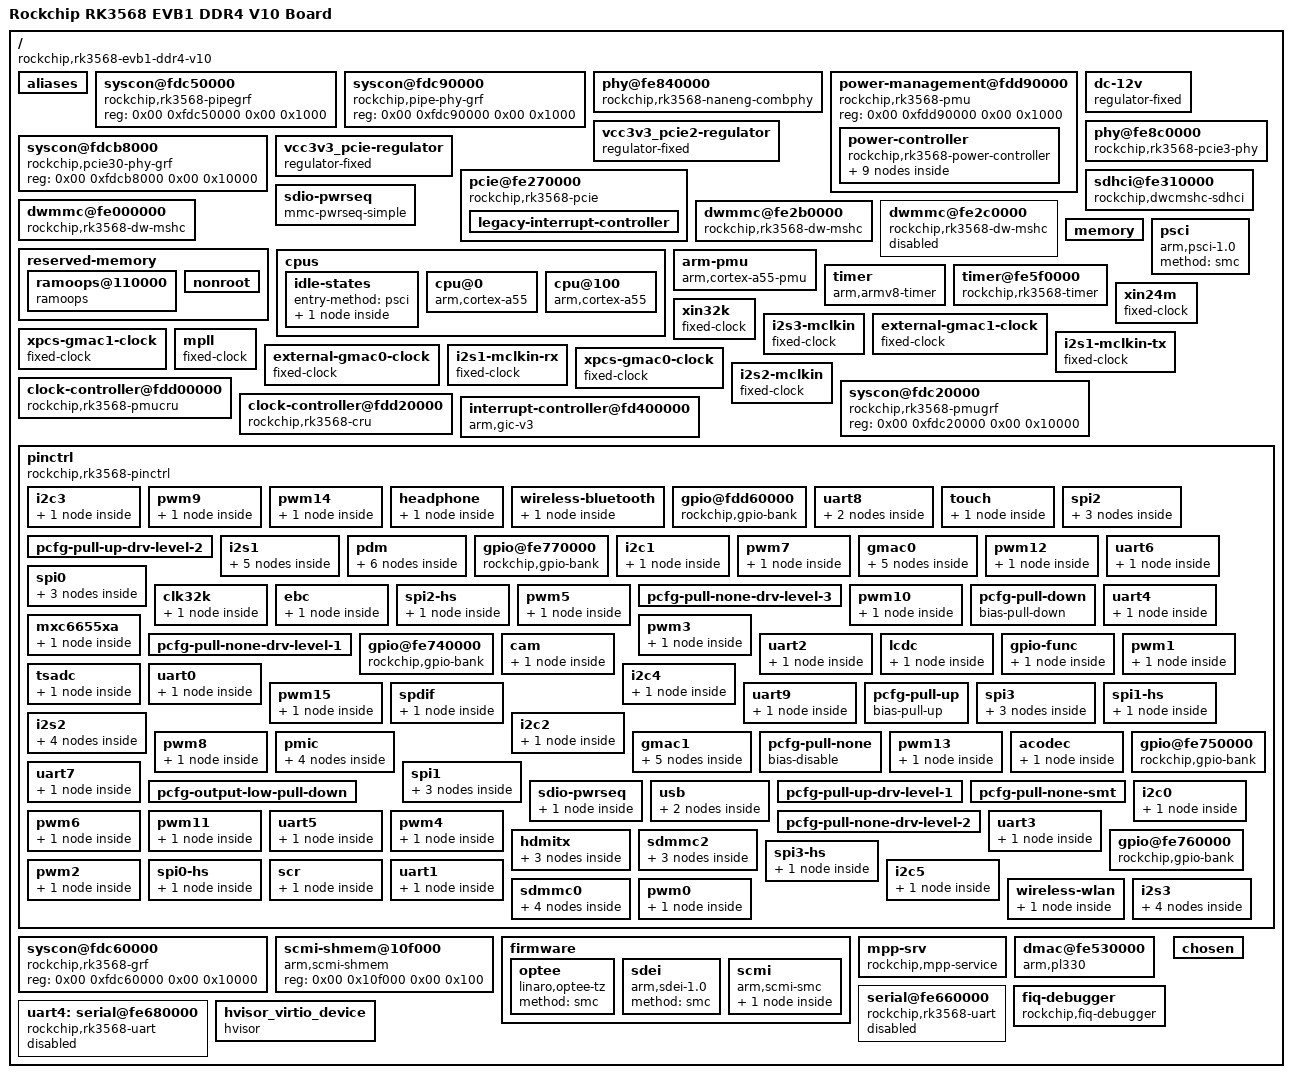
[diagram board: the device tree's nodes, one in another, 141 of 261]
/dts-v1/;

/{
    #address-cells = <0x02>;
	model = "Rockchip RK3568 EVB1 DDR4 V10 Board";
	serial-number = "7256eeaa4ea280de";
	#size-cells = <0x02>;
	interrupt-parent = <0x01>;
	compatible = "rockchip,rk3568-evb1-ddr4-v10\0rockchip,rk3568";

	aliases {
		mmc0 = "/sdhci@fe310000";
		serial2 = "/serial@fe660000";
		sdmmc2 = "/dwmmc@fe000000";
		serial4 = "/serial@fe680000";
		mmc1 = "/dwmmc@fe2b0000";
		mmc2 = "/dwmmc@fe2c0000";
		mmc3 = "/dwmmc@fe000000";
	};

	syscon@fdc50000 {
		compatible = "rockchip,rk3568-pipegrf\0syscon";
		reg = <0x00 0xfdc50000 0x00 0x1000>;
		phandle = <0x10d>;
	};

	syscon@fdc90000 {
		compatible = "rockchip,pipe-phy-grf\0syscon";
		reg = <0x00 0xfdc90000 0x00 0x1000>;
		phandle = <0x110>;
	};

	phy@fe840000 {
		rockchip,pipe-grf = <0x10d>;
		clock-names = "refclk\0apbclk\0pipe_clk";
		assigned-clocks = <0x33 0x25>;
		assigned-clock-rates = <0x5f5e100>;
		resets = <0x20 0x1c8 0x20 0x1c9>;
		clocks = <0x33 0x25 0x20 0x17e 0x20 0x7f>;
		#phy-cells = <0x01>;
		compatible = "rockchip,rk3568-naneng-combphy";
		status = "okay";
		rockchip,pipe-phy-grf = <0x110>;
		reg = <0x00 0xfe840000 0x00 0x100>;
		phandle = <0x24>;
		reset-names = "combphy-apb\0combphy";
	};

	power-management@fdd90000 {
		compatible = "rockchip,rk3568-pmu\0syscon\0simple-mfd";
		reg = <0x00 0xfdd90000 0x00 0x1000>;
		phandle = <0x177>;

		power-controller {
			#address-cells = <0x01>;
			#size-cells = <0x00>;
			#power-domain-cells = <0x01>;
			compatible = "rockchip,rk3568-power-controller";
			status = "okay";
			phandle = <0x22>;

			pd_pipe@15 {
				clocks = <0x20 0x7f>;
				reg = <0x0f>;
				pm_qos = <0x5a 0x5b 0x5c 0x5d 0x5e 0x5f 0x60 0x61>;
			};

			pd_vi@8 {
				clocks = <0x20 0xcc 0x20 0xcd>;
				reg = <0x08>;
				pm_qos = <0x49 0x4a 0x4b>;
			};

			pd_rkvenc@14 {
				clocks = <0x20 0x102>;
				reg = <0x0e>;
				pm_qos = <0x57 0x58 0x59>;
			};

			pd_rga@10 {
				clocks = <0x20 0xf1 0x20 0xf2>;
				reg = <0x0a>;
				pm_qos = <0x4f 0x50 0x51 0x52 0x53 0x54>;
			};

			pd_vpu@11 {
				clocks = <0x20 0xed>;
				reg = <0x0b>;
				pm_qos = <0x55>;
			};

			pd_gpu@7 {
				clocks = <0x20 0x19 0x20 0x1a>;
				reg = <0x07>;
				pm_qos = <0x48>;
			};

			pd_rkvdec@13 {
				clocks = <0x20 0x107>;
				reg = <0x0d>;
				pm_qos = <0x56>;
			};

			pd_vo@9 {
				clocks = <0x20 0xda 0x20 0xdb 0x20 0xdc>;
				reg = <0x09>;
				pm_qos = <0x4c 0x4d 0x4e>;
			};

			pd_npu@6 {
				clocks = <0x20 0x27 0x20 0x25 0x20 0x26>;
				reg = <0x06>;
				pm_qos = <0x47>;
			};
		};
	};

	dc-12v {
		regulator-max-microvolt = <0xb71b00>;
		regulator-boot-on;
		regulator-always-on;
		regulator-min-microvolt = <0xb71b00>;
		regulator-name = "dc_12v";
		compatible = "regulator-fixed";
		phandle = <0x131>;
	};

	vcc3v3_pcie2-regulator {
		regulator-max-microvolt = <0x325aa0>;
		regulator-boot-on;
		gpio = <0x38 0x17 0x00>;
		regulator-always-on;
		enable-active-high;
		regulator-min-microvolt = <0x325aa0>;
		regulator-name = "vcc3v3_pcie2";
		startup-delay-us = <0x1388>;
		compatible = "regulator-fixed";
		phandle = <0x1ea>;
		vin-supply = <0x131>;
	};


	// pcie@fe260000 {
	// 	power-domains = <0x22 0x0f>;
	// 	#address-cells = <0x03>;
	// 	phy-names = "pcie-phy";
	// 	bus-range = <0x00 0x0f>;
	// 	clock-names = "aclk_mst\0aclk_slv\0aclk_dbi\0pclk\0aux";
	// 	reg-names = "pcie-dbi\0pcie-apb";
	// 	num-ob-windows = <0x02>;
	// 	resets = <0x20 0xa1>;
	// 	interrupts = <0x00 0x4b 0x04 0x00 0x4a 0x04 0x00 0x49 0x04 0x00 0x48 0x04 0x00 0x47 0x04>;
	// 	clocks = <0x20 0x81 0x20 0x82 0x20 0x83 0x20 0x84 0x20 0x85>;
	// 	interrupt-map = <0x00 0x00 0x00 0x01 0xac 0x00 0x00 0x00 0x00 0x02 0xac 0x01 0x00 0x00 0x00 0x03 0xac 0x02 0x00 0x00 0x00 0x04 0xac 0x03>;
	// 	#size-cells = <0x02>;
	// 	max-link-speed = <0x02>;
	// 	device_type = "pci";
	// 	interrupt-map-mask = <0x00 0x00 0x00 0x07>;
	// 	reset-gpios = <0x83 0x11 0x00>;
	// 	num-lanes = <0x01>;
	// 	compatible = "rockchip,rk3568-pcie\0snps,dw-pcie";
	// 	ranges = <0x800 0x00 0xf4000000 0x00 0xf4000000 0x00 0x100000 0x81000000 0x00 0xf4100000 0x00 0xf4100000 0x00 0x100000 0x82000000 0x00 0xf4200000 0x00 0xf4200000 0x00 0x1e00000 0xc3000000 0x03 0x00 0x03 0x00 0x00 0x40000000>;
	// 	msi-map = <0x00 0xad 0x00 0x1000>;
	// 	#interrupt-cells = <0x01>;
	// 	status = "okay";
	// 	interrupt-names = "sys\0pmc\0msg\0legacy\0err";
	// 	phys = <0x24 0x02>;
	// 	num-viewport = <0x08>;
	// 	reg = <0x03 0xc0000000 0x00 0x400000 0x00 0xfe260000 0x00 0x10000>;
	// 	linux,pci-domain = <0x00>;
	// 	phandle = <0x19d>;
	// 	reset-names = "pipe";
	// 	num-ib-windows = <0x06>;

	// 	legacy-interrupt-controller {
	// 		#address-cells = <0x00>;
	// 		interrupts = <0x00 0x48 0x01>;
	// 		interrupt-parent = <0x01>;
	// 		#interrupt-cells = <0x01>;
	// 		phandle = <0xac>;
	// 		interrupt-controller;
	// 	};
	// };

	syscon@fdcb8000 {
		compatible = "rockchip,pcie30-phy-grf\0syscon";
		reg = <0x00 0xfdcb8000 0x00 0x10000>;
		phandle = <0x116>;
	};

	phy@fe8c0000 {
		clock-names = "refclk_m\0refclk_n\0pclk";
		resets = <0x20 0x1be>;
		clocks = <0x33 0x26 0x33 0x27 0x20 0x177>;
		#phy-cells = <0x00>;
		compatible = "rockchip,rk3568-pcie3-phy";
		status = "okay";
		reg = <0x00 0xfe8c0000 0x00 0x20000>;
		phandle = <0xaf>;
		reset-names = "phy";
		rockchip,phy-grf = <0x116>;
	};

	vcc3v3_pcie-regulator {
		regulator-max-microvolt = <0x325aa0>;
		regulator-boot-on;
		gpio = <0x38 0x1c 0x00>;
		regulator-always-on;
		enable-active-high;
		regulator-min-microvolt = <0x325aa0>;
		regulator-name = "vcc3v3_pcie";
		startup-delay-us = <0x3e8>;
		compatible = "regulator-fixed";
		phandle = <0xb0>;
		vin-supply = <0x131>;
	};

	pcie@fe270000 {
		power-domains = <0x22 0x0f>;
		vpcie3v3-supply = <0xb0>;
		#address-cells = <0x03>;
		phy-names = "pcie-phy";
		bus-range = <0x10 0x1f>;
		clock-names = "aclk_mst\0aclk_slv\0aclk_dbi\0pclk\0aux";
		reg-names = "pcie-dbi\0pcie-apb";
		num-ob-windows = <0x02>;
		resets = <0x20 0xb1>;
		interrupts = <0x00 0xa0 0x04 0x00 0x9f 0x04 0x00 0x9e 0x04 0x00 0x9d 0x04 0x00 0x9c 0x04>;
		clocks = <0x20 0x88 0x20 0x89 0x20 0x8a 0x20 0x8b 0x20 0x8c>;
		interrupt-map = <0x00 0x00 0x00 0x01 0xae 0x00 0x00 0x00 0x00 0x02 0xae 0x01 0x00 0x00 0x00 0x03 0xae 0x02 0x00 0x00 0x00 0x04 0xae 0x03>;
		#size-cells = <0x02>;
		max-link-speed = <0x03>;
		device_type = "pci";
		interrupt-map-mask = <0x00 0x00 0x00 0x07>;
		reset-gpios = <0x83 0x01 0x00>;
		num-lanes = <0x01>;
		compatible = "rockchip,rk3568-pcie\0snps,dw-pcie";
		ranges = <0x800 0x00 0xf2000000 0x00 0xf2000000 0x00 0x100000 0x81000000 0x00 0xf2100000 0x00 0xf2100000 0x00 0x100000 0x82000000 0x00 0xf2200000 0x00 0xf2200000 0x00 0x1e00000 0xc3000000 0x03 0x40000000 0x03 0x40000000 0x00 0x40000000>;
		msi-map = <0x1000 0xad 0x1000 0x1000>;
		#interrupt-cells = <0x01>;
		status = "okay";
		rockchip,bifurcation;
		interrupt-names = "sys\0pmc\0msg\0legacy\0err";
		phys = <0xaf>;
		num-viewport = <0x08>;
		reg = <0x03 0xc0400000 0x00 0x400000 0x00 0xfe270000 0x00 0x10000>;
		linux,pci-domain = <0x01>;
		phandle = <0x19e>;
		reset-names = "pipe";
		num-ib-windows = <0x06>;

		legacy-interrupt-controller {
			#address-cells = <0x00>;
			interrupts = <0x00 0x9d 0x01>;
			interrupt-parent = <0x01>;
			#interrupt-cells = <0x01>;
			phandle = <0xae>;
			interrupt-controller;
		};
	};

	// pcie@fe280000 {
	// 	power-domains = <0x22 0x0f>;
	// 	vpcie3v3-supply = <0xb0>;
	// 	#address-cells = <0x03>;
	// 	phy-names = "pcie-phy";
	// 	bus-range = <0x20 0x2f>;
	// 	clock-names = "aclk_mst\0aclk_slv\0aclk_dbi\0pclk\0aux";
	// 	reg-names = "pcie-dbi\0pcie-apb";
	// 	num-ob-windows = <0x02>;
	// 	resets = <0x20 0xc1>;
	// 	interrupts = <0x00 0xa5 0x04 0x00 0xa4 0x04 0x00 0xa3 0x04 0x00 0xa2 0x04 0x00 0xa1 0x04>;
	// 	clocks = <0x20 0x8f 0x20 0x90 0x20 0x91 0x20 0x92 0x20 0x93>;
	// 	interrupt-map = <0x00 0x00 0x00 0x01 0xb1 0x00 0x00 0x00 0x00 0x02 0xb1 0x01 0x00 0x00 0x00 0x03 0xb1 0x02 0x00 0x00 0x00 0x04 0xb1 0x03>;
	// 	#size-cells = <0x02>;
	// 	max-link-speed = <0x03>;
	// 	device_type = "pci";
	// 	interrupt-map-mask = <0x00 0x00 0x00 0x07>;
	// 	reset-gpios = <0xb2 0x1e 0x00>;
	// 	num-lanes = <0x02>;
	// 	compatible = "rockchip,rk3568-pcie\0snps,dw-pcie";
	// 	ranges = <0x800 0x00 0xf0000000 0x00 0xf0000000 0x00 0x100000 0x81000000 0x00 0xf0100000 0x00 0xf0100000 0x00 0x100000 0x82000000 0x00 0xf0200000 0x00 0xf0200000 0x00 0x1e00000 0xc3000000 0x03 0x80000000 0x03 0x80000000 0x00 0x40000000>;
	// 	msi-map = <0x2000 0xad 0x2000 0x1000>;
	// 	#interrupt-cells = <0x01>;
	// 	status = "okay";
	// 	interrupt-names = "sys\0pmc\0msg\0legacy\0err";
	// 	phys = <0xaf>;
	// 	num-viewport = <0x08>;
	// 	reg = <0x03 0xc0800000 0x00 0x400000 0x00 0xfe280000 0x00 0x10000>;
	// 	linux,pci-domain = <0x02>;
	// 	phandle = <0x19f>;
	// 	reset-names = "pipe";
	// 	num-ib-windows = <0x06>;

	// 	legacy-interrupt-controller {
	// 		#address-cells = <0x00>;
	// 		interrupts = <0x00 0xa2 0x01>;
	// 		interrupt-parent = <0x01>;
	// 		#interrupt-cells = <0x01>;
	// 		phandle = <0xb1>;
	// 		interrupt-controller;
	// 	};
	// };

	sdhci@fe310000 {
		clock-names = "core\0bus\0axi\0block\0timer";
		assigned-clocks = <0x20 0x7b 0x20 0x7d 0x20 0x7c>;
		bus-width = <0x08>;
		non-removable;
		assigned-clock-rates = <0xbebc200 0x16e3600 0xbebc200>;
		interrupts = <0x00 0x13 0x04>;
		clocks = <0x20 0x7c 0x20 0x7a 0x20 0x79 0x20 0x7b 0x20 0x7d>;
		compatible = "rockchip,dwcmshc-sdhci\0snps,dwcmshc-sdhci";
		status = "okay";
		reg = <0x00 0xfe310000 0x00 0x10000>;
		phandle = <0x1a5>;
		max-frequency = <0xbebc200>;
		supports-emmc;
	};

	sdio-pwrseq {
		pinctrl-names = "default";
		pinctrl-0 = <0x136>;
		clock-names = "ext_clock";
		clocks = <0x135 0x01>;
		reset-gpios = <0x83 0x1d 0x01>;
		compatible = "mmc-pwrseq-simple";
		post-power-on-delay-ms = <0xc8>;
		phandle = <0x9f>;
	};

	dwmmc@fe000000 {
		fifo-depth = <0x100>;
		pinctrl-names = "default";
		supports-sdio;
		pinctrl-0 = <0xa0 0xa1 0xa2>;
		clock-names = "biu\0ciu\0ciu-drive\0ciu-sample";
		cap-sd-highspeed;
		bus-width = <0x04>;
		non-removable;
		resets = <0x20 0xeb>;
		cap-sdio-irq;
		interrupts = <0x00 0x64 0x04>;
		clocks = <0x20 0xc1 0x20 0xc2 0x20 0x18e 0x20 0x18f>;
		keep-power-in-suspend;
		compatible = "rockchip,rk3568-dw-mshc\0rockchip,rk3288-dw-mshc";
		status = "okay";
		disable-wp;
		mmc-pwrseq = <0x9f>;
		reg = <0x00 0xfe000000 0x00 0x4000>;
		phandle = <0x19a>;
		sd-uhs-sdr104;
		max-frequency = <0x8f0d180>;
		reset-names = "reset";
	};

	dwmmc@fe2b0000 {
		supports-sd;
		fifo-depth = <0x100>;
		pinctrl-names = "default";
		pinctrl-0 = <0xbe 0xbf 0xc0 0xc1>;
		clock-names = "biu\0ciu\0ciu-drive\0ciu-sample";
		cap-sd-highspeed;
		vqmmc-supply = <0x2d>;
		bus-width = <0x04>;
		resets = <0x20 0xd4>;
		interrupts = <0x00 0x62 0x04>;
		clocks = <0x20 0xb0 0x20 0xb1 0x20 0x18a 0x20 0x18b>;
		vmmc-supply = <0xbd>;
		compatible = "rockchip,rk3568-dw-mshc\0rockchip,rk3288-dw-mshc";
		status = "okay";
		disable-wp;
		reg = <0x00 0xfe2b0000 0x00 0x4000>;
		phandle = <0x1a2>;
		sd-uhs-sdr104;
		max-frequency = <0x8f0d180>;
		cap-mmc-highspeed;
		reset-names = "reset";
	};

	dwmmc@fe2c0000 {
		fifo-depth = <0x100>;
		clock-names = "biu\0ciu\0ciu-drive\0ciu-sample";
		resets = <0x20 0xd6>;
		interrupts = <0x00 0x63 0x04>;
		clocks = <0x20 0xb2 0x20 0xb3 0x20 0x18c 0x20 0x18d>;
		compatible = "rockchip,rk3568-dw-mshc\0rockchip,rk3288-dw-mshc";
		status = "disabled";
		reg = <0x00 0xfe2c0000 0x00 0x4000>;
		phandle = <0x1a3>;
		max-frequency = <0x8f0d180>;
		reset-names = "reset";
	};
    
    memory {
		device_type = "memory";
		reg = <0x00 0x200000 0x00 0x8200000 0x00 0x9400000 0x00 0xe6c00000 0x01 0xf0000000 0x00 0x10000000>;
	};

    // memory {
	// 	device_type = "memory";
	// 	reg = <0x00 0x60000000 0x00 0x20000000>;
	// };

	reserved-memory {
		#address-cells = <0x02>;
		#size-cells = <0x02>;
		ranges;
		phandle = <0x142>;

        ramoops@110000 {
			record-size = <0x20000>;
			pmsg-size = <0x50000>;
			compatible = "ramoops";
			console-size = <0x80000>;
			reg = <0x00 0x110000 0x00 0xf0000>;
			phandle = <0x143>;
			ftrace-size = <0x00>;
		};

        // hvisor@0x2000000 {
		// 	no-map;
		// 	reg = <0x00 0x2000000 0x00 0x1000000>;
		// };

		nonroot {
			no-map;
			reg = <0x00 0x40000000 0x00 0x20000000>;
		};
    };

	cpus {
		#address-cells = <0x02>;
		#size-cells = <0x00>;

		idle-states {
			entry-method = "psci";

			cpu-sleep {
				entry-latency-us = <0x64>;
				local-timer-stop;
				exit-latency-us = <0x78>;
				arm,psci-suspend-param = <0x10000>;
				compatible = "arm,idle-state";
				phandle = <0x04>;
				min-residency-us = <0x3e8>;
			};
		};

		cpu@0 {
			cpu-supply = <0x05>;
			clocks = <0x02 0x00>;
			cpu-idle-states = <0x04>;
			device_type = "cpu";
			compatible = "arm,cortex-a55";
			dynamic-power-coefficient = <0xbb>;
			reg = <0x00 0x00>;
			enable-method = "psci";
			phandle = <0x0a>;
			// operating-points-v2 = <0x03>;
			#cooling-cells = <0x02>;
		};

		cpu@100 {
			clocks = <0x02 0x00>;
			cpu-idle-states = <0x04>;
			device_type = "cpu";
			compatible = "arm,cortex-a55";
			reg = <0x00 0x100>;
			enable-method = "psci";
			phandle = <0x0b>;
			// operating-points-v2 = <0x03>;
		};

		// cpu@200 {
		// 	clocks = <0x02 0x00>;
		// 	cpu-idle-states = <0x04>;
		// 	device_type = "cpu";
		// 	compatible = "arm,cortex-a55";
		// 	reg = <0x00 0x200>;
		// 	enable-method = "psci";
		// 	phandle = <0x0c>;
		// 	operating-points-v2 = <0x03>;
		// };

		// cpu@300 {
		// 	clocks = <0x02 0x00>;
		// 	cpu-idle-states = <0x04>;
		// 	device_type = "cpu";
		// 	compatible = "arm,cortex-a55";
		// 	reg = <0x00 0x300>;
		// 	enable-method = "psci";
		// 	phandle = <0x0d>;
		// 	operating-points-v2 = <0x03>;
		// };
	};

	psci {
		method = "smc";
		compatible = "arm,psci-1.0";
	};

    arm-pmu {
		interrupt-affinity = <0x0a 0x0b 0x0c 0x0d>;
		interrupts = <0x00 0xe4 0x04 0x00 0xe5 0x04 0x00 0xe6 0x04 0x00 0xe7 0x04>;
		compatible = "arm,cortex-a55-pmu\0arm,armv8-pmuv3";
	};

    timer {
		arm,no-tick-in-suspend;
		interrupts = <0x01 0x0d 0xf04 0x01 0x0e 0xf04 0x01 0x0b 0xf04 0x01 0x0a 0xf04>;
		compatible = "arm,armv8-timer";
	};

	timer@fe5f0000 {
		clock-names = "pclk\0timer";
		interrupts = <0x00 0x6d 0x04>;
		clocks = <0x20 0x16c 0x20 0x16d>;
		compatible = "rockchip,rk3568-timer\0rockchip,rk3288-timer";
		reg = <0x00 0xfe5f0000 0x00 0x1000>;
		phandle = <0x1b6>;
	};

	xin24m {
		clock-output-names = "xin24m";
		#clock-cells = <0x00>;
		clock-frequency = <0x16e3600>;
		compatible = "fixed-clock";
		phandle = <0x154>;
	};

    xin32k {
		pinctrl-names = "default";
		clock-output-names = "xin32k";
		pinctrl-0 = <0x1f>;
		#clock-cells = <0x00>;
		clock-frequency = <0x8000>;
		compatible = "fixed-clock";
		phandle = <0x155>;
	};

	i2s3-mclkin {
		clock-output-names = "i2s3_mclkin";
		#clock-cells = <0x00>;
		clock-frequency = <0xbb8000>;
		compatible = "fixed-clock";
		phandle = <0x152>;
	};

	external-gmac1-clock {
		clock-output-names = "gmac1_clkin";
		#clock-cells = <0x00>;
		clock-frequency = <0x7735940>;
		compatible = "fixed-clock";
		phandle = <0x14c>;
	};

	xpcs-gmac1-clock {
		clock-output-names = "clk_gmac1_xpcs_mii";
		#clock-cells = <0x00>;
		clock-frequency = <0x7735940>;
		compatible = "fixed-clock";
		phandle = <0x14e>;
	};

	mpll {
		clock-output-names = "mpll";
		#clock-cells = <0x00>;
		clock-frequency = <0x2faf0800>;
		compatible = "fixed-clock";
		phandle = <0x153>;
	};

	i2s1-mclkin-tx {
		clock-output-names = "i2s1_mclkin_tx";
		#clock-cells = <0x00>;
		clock-frequency = <0xbb8000>;
		compatible = "fixed-clock";
		phandle = <0x150>;
	};

	external-gmac0-clock {
		clock-output-names = "gmac0_clkin";
		#clock-cells = <0x00>;
		clock-frequency = <0x7735940>;
		compatible = "fixed-clock";
		phandle = <0x14b>;
	};

	i2s1-mclkin-rx {
		clock-output-names = "i2s1_mclkin_rx";
		#clock-cells = <0x00>;
		clock-frequency = <0xbb8000>;
		compatible = "fixed-clock";
		phandle = <0x14f>;
	};

	xpcs-gmac0-clock {
		clock-output-names = "clk_gmac0_xpcs_mii";
		#clock-cells = <0x00>;
		clock-frequency = <0x7735940>;
		compatible = "fixed-clock";
		phandle = <0x14d>;
	};

	i2s2-mclkin {
		clock-output-names = "i2s2_mclkin";
		#clock-cells = <0x00>;
		clock-frequency = <0xbb8000>;
		compatible = "fixed-clock";
		phandle = <0x151>;
	};

	syscon@fdc20000 {
		compatible = "rockchip,rk3568-pmugrf\0syscon\0simple-mfd";
		reg = <0x00 0xfdc20000 0x00 0x10000>;
		phandle = <0x35>;
	};

	clock-controller@fdd00000 {
		#reset-cells = <0x01>;
		assigned-clocks = <0x33 0x32>;
		assigned-clock-parents = <0x33 0x05>;
		#clock-cells = <0x01>;
		rockchip,pmugrf = <0x35>;
		compatible = "rockchip,rk3568-pmucru";
		rockchip,grf = <0x34>;
		reg = <0x00 0xfdd00000 0x00 0x1000>;
		phandle = <0x33>;
	};

	clock-controller@fdd20000 {
		#reset-cells = <0x01>;
		assigned-clocks = <0x33 0x05 0x20 0x106 0x20 0x10b 0x33 0x01 0x33 0x2b 0x20 0x03 0x20 0x19b 0x20 0x09 0x20 0x19c 0x20 0x19d 0x20 0x1a1 0x20 0x19e 0x20 0x19f 0x20 0x1a0 0x20 0x04 0x20 0x10d 0x20 0x10e 0x20 0x173 0x20 0x174 0x20 0x175 0x20 0x176 0x20 0xc9 0x20 0xca 0x20 0x06 0x20 0x7e 0x20 0x7f 0x20 0x3d 0x20 0x41 0x20 0x45 0x20 0x49 0x20 0x4d 0x20 0x4d 0x20 0x55 0x20 0x51 0x20 0x5d 0x20 0xdd>;
		assigned-clock-parents = <0x33 0x08 0x20 0x04 0x20 0x04>;
		assigned-clock-rates = <0x8000 0x11e1a300 0x11e1a300 0xbebc200 0x5f5e100 0x3b9aca00 0x1dcd6500 0x13d92d40 0xee6b280 0x7735940 0x5f5e100 0x3b9aca0 0x2faf080 0x17d7840 0x46cf7100 0x8f0d180 0x5f5e100 0x1dcd6500 0x17d78400 0x8f0d180 0x5f5e100 0x11e1a300 0x8f0d180 0x47868c00 0x17d78400 0x5f5e100 0x46cf7100 0x46cf7100 0x46cf7100 0x46cf7100 0x46cf7100 0x46cf7100 0x46cf7100 0x46cf7100 0x46cf7100 0x1dcd6500>;
		#clock-cells = <0x01>;
		compatible = "rockchip,rk3568-cru";
		rockchip,grf = <0x34>;
		reg = <0x00 0xfdd20000 0x00 0x1000>;
		phandle = <0x20>;
	};

	interrupt-controller@fd400000 {
		#address-cells = <0x02>;
		interrupts = <0x01 0x09 0x04>;
		#size-cells = <0x02>;
		compatible = "arm,gic-v3";
		ranges;
		#interrupt-cells = <0x03>;
		reg = <0x00 0xfd400000 0x00 0x10000 0x00 0xfd460000 0x00 0xc0000>;
		phandle = <0x01>;
		interrupt-controller;

		// interrupt-controller@fd440000 {
		// 	msi-controller;
		// 	compatible = "arm,gic-v3-its";
		// 	reg = <0x00 0xfd440000 0x00 0x20000>;
		// 	phandle = <0xad>;
		// 	#msi-cells = <0x01>;
		// };
	};


    pinctrl {
		#address-cells = <0x02>;
		#size-cells = <0x02>;
		compatible = "rockchip,rk3568-pinctrl";
		rockchip,pmu = <0x35>;
		ranges;
		rockchip,grf = <0x34>;
		phandle = <0x117>;

		i2c3 {
			i2c3m0-xfer {
				rockchip,pins = <0x01 0x01 0x01 0x11d 0x01 0x00 0x01 0x11d>;
				phandle = <0xdb>;
			};
		};

		pwm9 {

			pwm9m0-pins {
				rockchip,pins = <0x03 0x0a 0x05 0x118>;
				phandle = <0xfd>;
			};
		};

		pwm14 {

			pwm14m0-pins {
				rockchip,pins = <0x03 0x14 0x01 0x118>;
				phandle = <0x102>;
			};
		};

		headphone {

			hp-det {
				rockchip,pins = <0x03 0x12 0x00 0x121>;
				phandle = <0x12d>;
			};
		};

		wireless-bluetooth {

			uart8-gpios {
				rockchip,pins = <0x02 0x09 0x00 0x118>;
				phandle = <0x1d9>;
			};
		};

		gpio@fdd60000 {
			gpio-controller;
			interrupts = <0x00 0x21 0x04>;
			clocks = <0x33 0x2e 0x33 0x0c>;
			compatible = "rockchip,gpio-bank";
			#interrupt-cells = <0x02>;
			reg = <0x00 0xfdd60000 0x00 0x100>;
			phandle = <0x38>;
			#gpio-cells = <0x02>;
			gpio-ranges = <0x117 0x00 0x00 0x20>;
			interrupt-controller;
		};

		uart8 {

			uart8m0-ctsn {
				rockchip,pins = <0x02 0x0a 0x03 0x118>;
				phandle = <0xf6>;
			};

			uart8m0-xfer {
				rockchip,pins = <0x02 0x16 0x02 0x11a 0x02 0x15 0x03 0x11a>;
				phandle = <0xf5>;
			};
		};

		touch {

			touch-gpio {
				rockchip,pins = <0x00 0x0d 0x00 0x11a 0x00 0x0e 0x00 0x118>;
				phandle = <0x1d8>;
			};
		};

		spi2 {

			spi2m0-cs1 {
				rockchip,pins = <0x02 0x15 0x04 0x118>;
				phandle = <0xe7>;
			};

			spi2m0-cs0 {
				rockchip,pins = <0x02 0x14 0x04 0x118>;
				phandle = <0xe6>;
			};

			spi2m0-pins {
				rockchip,pins = <0x02 0x11 0x04 0x118 0x02 0x12 0x04 0x118 0x02 0x13 0x04 0x118>;
				phandle = <0xe8>;
			};
		};

		pcfg-pull-up-drv-level-2 {
			drive-strength = <0x02>;
			phandle = <0x119>;
			bias-pull-up;
		};

		i2s1 {

			i2s1m0-lrcktx {
				rockchip,pins = <0x01 0x05 0x01 0x118>;
				phandle = <0xc4>;
			};

			i2s1m0-mclk {
				rockchip,pins = <0x01 0x02 0x01 0x118>;
				phandle = <0x40>;
			};

			i2s1m0-sclktx {
				rockchip,pins = <0x01 0x03 0x01 0x118>;
				phandle = <0xc3>;
			};

			i2s1m0-sdo0 {
				rockchip,pins = <0x01 0x07 0x01 0x118>;
				phandle = <0xc6>;
			};

			i2s1m0-sdi0 {
				rockchip,pins = <0x01 0x0b 0x01 0x118>;
				phandle = <0xc5>;
			};
		};

		pdm {

			pdmm0-sdi3 {
				rockchip,pins = <0x01 0x08 0x03 0x118>;
				phandle = <0xd4>;
			};

			pdmm0-sdi1 {
				rockchip,pins = <0x01 0x0a 0x03 0x118>;
				phandle = <0xd2>;
			};

			pdmm0-clk1 {
				rockchip,pins = <0x01 0x04 0x03 0x118>;
				phandle = <0xd0>;
			};

			pdmm0-sdi2 {
				rockchip,pins = <0x01 0x09 0x03 0x118>;
				phandle = <0xd3>;
			};

			pdmm0-sdi0 {
				rockchip,pins = <0x01 0x0b 0x02 0x118>;
				phandle = <0xd1>;
			};

			pdmm0-clk {
				rockchip,pins = <0x01 0x06 0x03 0x118>;
				phandle = <0xcf>;
			};
		};

		gpio@fe770000 {
			gpio-controller;
			interrupts = <0x00 0x25 0x04>;
			clocks = <0x20 0x169 0x20 0x16a>;
			compatible = "rockchip,gpio-bank";
			#interrupt-cells = <0x02>;
			reg = <0x00 0xfe770000 0x00 0x100>;
			phandle = <0x1d4>;
			#gpio-cells = <0x02>;
			gpio-ranges = <0x117 0x00 0x80 0x20>;
			interrupt-controller;
		};

		i2c1 {

			i2c1-xfer {
				rockchip,pins = <0x00 0x0b 0x01 0x11d 0x00 0x0c 0x01 0x11d>;
				phandle = <0xd9>;
			};
		};

		pwm7 {

			pwm7-pins {
				rockchip,pins = <0x00 0x16 0x01 0x118>;
				phandle = <0xfb>;
			};
		};

		gmac0 {

			gmac0-miim {
				rockchip,pins = <0x02 0x13 0x02 0x118 0x02 0x14 0x02 0x118>;
				phandle = <0xb7>;
			};

			gmac0-tx-bus2 {
				rockchip,pins = <0x02 0x0b 0x01 0x11b 0x02 0x0c 0x01 0x11b 0x02 0x0d 0x01 0x118>;
				phandle = <0xb8>;
			};

			gmac0-rgmii-bus {
				rockchip,pins = <0x02 0x03 0x02 0x118 0x02 0x04 0x02 0x118 0x02 0x06 0x02 0x11b 0x02 0x07 0x02 0x11b>;
				phandle = <0xbb>;
			};

			gmac0-rx-bus2 {
				rockchip,pins = <0x02 0x0e 0x01 0x118 0x02 0x0f 0x02 0x118 0x02 0x10 0x02 0x118>;
				phandle = <0xb9>;
			};

			gmac0-rgmii-clk {
				rockchip,pins = <0x02 0x05 0x02 0x118 0x02 0x08 0x02 0x11c>;
				phandle = <0xba>;
			};
		};

		pwm12 {

			pwm12m0-pins {
				rockchip,pins = <0x03 0x0f 0x02 0x118>;
				phandle = <0x100>;
			};
		};

		uart6 {

			uart6m0-xfer {
				rockchip,pins = <0x02 0x03 0x03 0x11a 0x02 0x04 0x03 0x11a>;
				phandle = <0xf3>;
			};
		};

		spi0 {

			spi0m0-cs0 {
				rockchip,pins = <0x00 0x16 0x02 0x118>;
				phandle = <0xde>;
			};

			spi0m0-cs1 {
				rockchip,pins = <0x00 0x14 0x02 0x118>;
				phandle = <0xdf>;
			};

			spi0m0-pins {
				rockchip,pins = <0x00 0x0d 0x02 0x118 0x00 0x15 0x02 0x118 0x00 0x0e 0x02 0x118>;
				phandle = <0xe0>;
			};
		};

		clk32k {

			clk32k-out0 {
				rockchip,pins = <0x00 0x08 0x02 0x118>;
				phandle = <0x1f>;
			};
		};

		ebc {

			ebc-pins {
				rockchip,pins = <0x04 0x10 0x02 0x118 0x04 0x0b 0x02 0x118 0x04 0x0c 0x02 0x118 0x04 0x06 0x02 0x118 0x04 0x11 0x02 0x118 0x03 0x16 0x02 0x118 0x03 0x17 0x02 0x118 0x03 0x18 0x02 0x118 0x03 0x19 0x02 0x118 0x03 0x1a 0x02 0x118 0x03 0x1b 0x02 0x118 0x03 0x1c 0x02 0x118 0x03 0x1d 0x02 0x118 0x03 0x1e 0x02 0x118 0x03 0x1f 0x02 0x118 0x04 0x00 0x02 0x118 0x04 0x01 0x02 0x118 0x04 0x02 0x02 0x118 0x04 0x03 0x02 0x118 0x04 0x04 0x02 0x118 0x04 0x05 0x02 0x118 0x04 0x0e 0x02 0x118 0x04 0x0f 0x02 0x118>;
				phandle = <0x6f>;
			};
		};

		spi2-hs {

			spi2m0-pins {
				rockchip,pins = <0x02 0x11 0x04 0x11f 0x02 0x12 0x04 0x11f 0x02 0x13 0x04 0x11f>;
				phandle = <0xe9>;
			};
		};

		pwm5 {

			pwm5-pins {
				rockchip,pins = <0x00 0x14 0x01 0x118>;
				phandle = <0xf9>;
			};
		};

		pcfg-pull-none-drv-level-3 {
			drive-strength = <0x03>;
			bias-disable;
			phandle = <0x120>;
		};

		pwm10 {

			pwm10m0-pins {
				rockchip,pins = <0x03 0x0d 0x05 0x118>;
				phandle = <0xfe>;
			};
		};

		pcfg-pull-down {
			bias-pull-down;
			phandle = <0x121>;
		};

		uart4 {

			uart4m1-xfer {
				rockchip,pins = <0x03 0x09 0x04 0x11a 0x03 0x0a 0x04 0x11a>;
				phandle = <0xf1>;
			};
		};

		mxc6655xa {

			mxc6655xa_irq_gpio {
				rockchip,pins = <0x03 0x11 0x00 0x118>;
				phandle = <0x1d7>;
			};
		};

		pwm3 {

			pwm3-pins {
				rockchip,pins = <0x00 0x12 0x01 0x118>;
				phandle = <0x46>;
			};
		};

		pcfg-pull-none-drv-level-1 {
			drive-strength = <0x01>;
			bias-disable;
			phandle = <0x11c>;
		};

		gpio@fe740000 {
			gpio-controller;
			interrupts = <0x00 0x22 0x04>;
			clocks = <0x20 0x163 0x20 0x164>;
			compatible = "rockchip,gpio-bank";
			#interrupt-cells = <0x02>;
			reg = <0x00 0xfe740000 0x00 0x100>;
			phandle = <0x1d3>;
			#gpio-cells = <0x02>;
			gpio-ranges = <0x117 0x00 0x20 0x20>;
			interrupt-controller;
		};

		cam {

			camera-pwr {
				rockchip,pins = <0x00 0x11 0x00 0x118>;
				phandle = <0x1d5>;
			};
		};

		uart2 {

			uart2m0-xfer {
				rockchip,pins = <0x00 0x18 0x01 0x11a 0x00 0x19 0x01 0x11a>;
				phandle = <0xef>;
			};
		};

		lcdc {

			lcdc-ctl {
				rockchip,pins = <0x03 0x00 0x01 0x118 0x02 0x18 0x01 0x118 0x02 0x19 0x01 0x118 0x02 0x1a 0x01 0x118 0x02 0x1b 0x01 0x118 0x02 0x1c 0x01 0x118 0x02 0x1d 0x01 0x118 0x02 0x1e 0x01 0x118 0x02 0x1f 0x01 0x118 0x03 0x01 0x01 0x118 0x03 0x02 0x01 0x118 0x03 0x03 0x01 0x118 0x03 0x04 0x01 0x118 0x03 0x05 0x01 0x118 0x03 0x06 0x01 0x118 0x03 0x07 0x01 0x118 0x03 0x08 0x01 0x118 0x03 0x09 0x01 0x118 0x03 0x0a 0x01 0x118 0x03 0x0b 0x01 0x118 0x03 0x0c 0x01 0x118 0x03 0x0d 0x01 0x118 0x03 0x0e 0x01 0x118 0x03 0x0f 0x01 0x118 0x03 0x10 0x01 0x118 0x03 0x13 0x01 0x118 0x03 0x11 0x01 0x118 0x03 0x12 0x01 0x118>;
				phandle = <0x32>;
			};
		};

		gpio-func {

			tsadc-gpio-func {
				rockchip,pins = <0x00 0x01 0x00 0x118>;
				phandle = <0x106>;
			};
		};

		pwm1 {

			pwm1m0-pins {
				rockchip,pins = <0x00 0x10 0x01 0x118>;
				phandle = <0x44>;
			};
		};

		tsadc {

			tsadc-shutorg {
				rockchip,pins = <0x00 0x01 0x02 0x118>;
				phandle = <0x107>;
			};
		};

		uart0 {

			uart0-xfer {
				rockchip,pins = <0x00 0x10 0x03 0x11a 0x00 0x11 0x03 0x11a>;
				phandle = <0x42>;
			};
		};

		i2c4 {

			i2c4m0-xfer {
				rockchip,pins = <0x04 0x0b 0x01 0x11d 0x04 0x0a 0x01 0x11d>;
				phandle = <0xdc>;
			};
		};

		pwm15 {

			pwm15m0-pins {
				rockchip,pins = <0x03 0x15 0x01 0x118>;
				phandle = <0x103>;
			};
		};

		spdif {

			spdifm1-tx {
				rockchip,pins = <0x03 0x15 0x02 0x118>;
				phandle = <0xd6>;
			};
		};

		uart9 {

			uart9m0-xfer {
				rockchip,pins = <0x02 0x07 0x03 0x11a 0x02 0x08 0x03 0x11a>;
				phandle = <0xf7>;
			};
		};

		pcfg-pull-up {
			phandle = <0x11a>;
			bias-pull-up;
		};

		spi3 {

			spi3m0-cs1 {
				rockchip,pins = <0x04 0x07 0x04 0x118>;
				phandle = <0xeb>;
			};

			spi3m0-pins {
				rockchip,pins = <0x04 0x0b 0x04 0x118 0x04 0x08 0x04 0x118 0x04 0x0a 0x04 0x118>;
				phandle = <0xec>;
			};

			spi3m0-cs0 {
				rockchip,pins = <0x04 0x06 0x04 0x118>;
				phandle = <0xea>;
			};
		};

		spi1-hs {

			spi1m0-pins {
				rockchip,pins = <0x02 0x0d 0x03 0x11f 0x02 0x0e 0x03 0x11f 0x02 0x0f 0x04 0x11f>;
				phandle = <0xe5>;
			};
		};

		i2s2 {

			i2s2m0-lrcktx {
				rockchip,pins = <0x02 0x13 0x01 0x118>;
				phandle = <0xc8>;
			};

			i2s2m0-sdi {
				rockchip,pins = <0x02 0x15 0x01 0x118>;
				phandle = <0xc9>;
			};

			i2s2m0-sclktx {
				rockchip,pins = <0x02 0x12 0x01 0x118>;
				phandle = <0xc7>;
			};

			i2s2m0-sdo {
				rockchip,pins = <0x02 0x14 0x01 0x118>;
				phandle = <0xca>;
			};
		};

		i2c2 {

			i2c2m0-xfer {
				rockchip,pins = <0x00 0x0d 0x01 0x11d 0x00 0x0e 0x01 0x11d>;
				phandle = <0xda>;
			};
		};

		pwm8 {

			pwm8m0-pins {
				rockchip,pins = <0x03 0x09 0x05 0x118>;
				phandle = <0xfc>;
			};
		};

		pmic {

			soc_slppin_gpio {
				rockchip,pins = <0x00 0x02 0x00 0x11e>;
				phandle = <0x3c>;
			};

			soc_slppin_slp {
				rockchip,pins = <0x00 0x02 0x01 0x11a>;
				phandle = <0x3a>;
			};

			pmic_int {
				rockchip,pins = <0x00 0x03 0x00 0x11a>;
				phandle = <0x39>;
			};

			soc_slppin_rst {
				rockchip,pins = <0x00 0x02 0x02 0x118>;
				phandle = <0x1d6>;
			};
		};

		gmac1 {

			gmac1m1-rgmii-clk {
				rockchip,pins = <0x04 0x03 0x03 0x118 0x04 0x00 0x03 0x11c>;
				phandle = <0x87>;
			};

			gmac1m1-miim {
				rockchip,pins = <0x04 0x0e 0x03 0x118 0x04 0x0f 0x03 0x118>;
				phandle = <0x84>;
			};

			gmac1m1-tx-bus2 {
				rockchip,pins = <0x04 0x04 0x03 0x11b 0x04 0x05 0x03 0x11b 0x04 0x06 0x03 0x118>;
				phandle = <0x85>;
			};

			gmac1m1-rgmii-bus {
				rockchip,pins = <0x04 0x01 0x03 0x118 0x04 0x02 0x03 0x118 0x03 0x1e 0x03 0x11b 0x03 0x1f 0x03 0x11b>;
				phandle = <0x88>;
			};

			gmac1m1-rx-bus2 {
				rockchip,pins = <0x04 0x07 0x03 0x118 0x04 0x08 0x03 0x118 0x04 0x09 0x03 0x118>;
				phandle = <0x86>;
			};
		};

		pcfg-pull-none {
			bias-disable;
			phandle = <0x118>;
		};

		pwm13 {

			pwm13m0-pins {
				rockchip,pins = <0x03 0x10 0x02 0x118>;
				phandle = <0x101>;
			};
		};

		acodec {

			acodec-pins {
				rockchip,pins = <0x01 0x09 0x05 0x118 0x01 0x01 0x05 0x118 0x01 0x00 0x05 0x118 0x01 0x07 0x05 0x118 0x01 0x08 0x05 0x118 0x01 0x03 0x05 0x118 0x01 0x05 0x05 0x118>;
				phandle = <0xd7>;
			};
		};

		gpio@fe750000 {
			gpio-controller;
			interrupts = <0x00 0x23 0x04>;
			clocks = <0x20 0x165 0x20 0x166>;
			compatible = "rockchip,gpio-bank";
			#interrupt-cells = <0x02>;
			reg = <0x00 0xfe750000 0x00 0x100>;
			phandle = <0xb2>;
			#gpio-cells = <0x02>;
			gpio-ranges = <0x117 0x00 0x40 0x20>;
			interrupt-controller;
		};

		uart7 {

			uart7m1-xfer {
				rockchip,pins = <0x03 0x15 0x04 0x11a 0x03 0x14 0x04 0x11a>;
				phandle = <0xf4>;
			};
		};

		spi1 {

			spi1m0-cs0 {
				rockchip,pins = <0x02 0x10 0x04 0x118>;
				phandle = <0xe2>;
			};

			spi1m0-pins {
				rockchip,pins = <0x02 0x0d 0x03 0x118 0x02 0x0e 0x03 0x118 0x02 0x0f 0x04 0x118>;
				phandle = <0xe4>;
			};

			spi1m0-cs1 {
				rockchip,pins = <0x02 0x16 0x03 0x118>;
				phandle = <0xe3>;
			};
		};

		pcfg-output-low-pull-down {
			bias-pull-down;
			phandle = <0x11e>;
			output-low;
		};

		sdio-pwrseq {

			wifi-enable-h {
				rockchip,pins = <0x03 0x1d 0x00 0x118>;
				phandle = <0x136>;
			};
		};

		usb {

			vcc5v0-host-en {
				rockchip,pins = <0x00 0x06 0x00 0x118>;
				phandle = <0x133>;
			};

			vcc5v0-otg-en {
				rockchip,pins = <0x03 0x03 0x00 0x118>;
				phandle = <0x134>;
			};
		};

		pcfg-pull-up-drv-level-1 {
			drive-strength = <0x01>;
			phandle = <0x11f>;
			bias-pull-up;
		};

		pcfg-pull-none-smt {
			bias-disable;
			input-schmitt-enable;
			phandle = <0x11d>;
		};

		i2c0 {

			i2c0-xfer {
				rockchip,pins = <0x00 0x09 0x01 0x11d 0x00 0x0a 0x01 0x11d>;
				phandle = <0x36>;
			};
		};

		pwm6 {

			pwm6-pins {
				rockchip,pins = <0x00 0x15 0x01 0x118>;
				phandle = <0xfa>;
			};
		};

		pwm11 {

			pwm11m0-pins {
				rockchip,pins = <0x03 0x0e 0x05 0x118>;
				phandle = <0xff>;
			};
		};

		uart5 {

			uart5m0-xfer {
				rockchip,pins = <0x02 0x01 0x03 0x11a 0x02 0x02 0x03 0x11a>;
				phandle = <0xf2>;
			};
		};

		pwm4 {

			pwm4-pins {
				rockchip,pins = <0x00 0x13 0x01 0x118>;
				phandle = <0xf8>;
			};
		};

		pcfg-pull-none-drv-level-2 {
			drive-strength = <0x02>;
			bias-disable;
			phandle = <0x11b>;
		};

		uart3 {

			uart3m0-xfer {
				rockchip,pins = <0x01 0x00 0x02 0x11a 0x01 0x01 0x02 0x11a>;
				phandle = <0xf0>;
			};
		};

		hdmitx {

			hdmitx-scl {
				rockchip,pins = <0x04 0x17 0x01 0x118>;
				phandle = <0x99>;
			};

			hdmitx-sda {
				rockchip,pins = <0x04 0x18 0x01 0x118>;
				phandle = <0x9a>;
			};

			hdmitxm0-cec {
				rockchip,pins = <0x04 0x19 0x01 0x118>;
				phandle = <0x9b>;
			};
		};

		sdmmc2 {

			sdmmc2m0-cmd {
				rockchip,pins = <0x03 0x1a 0x03 0x119>;
				phandle = <0xa1>;
			};

			sdmmc2m0-clk {
				rockchip,pins = <0x03 0x1b 0x03 0x119>;
				phandle = <0xa2>;
			};

			sdmmc2m0-bus4 {
				rockchip,pins = <0x03 0x16 0x03 0x119 0x03 0x17 0x03 0x119 0x03 0x18 0x03 0x119 0x03 0x19 0x03 0x119>;
				phandle = <0xa0>;
			};
		};

		gpio@fe760000 {
			gpio-controller;
			interrupts = <0x00 0x24 0x04>;
			clocks = <0x20 0x167 0x20 0x168>;
			compatible = "rockchip,gpio-bank";
			#interrupt-cells = <0x02>;
			reg = <0x00 0xfe760000 0x00 0x100>;
			phandle = <0x83>;
			#gpio-cells = <0x02>;
			gpio-ranges = <0x117 0x00 0x60 0x20>;
			interrupt-controller;
		};

		spi3-hs {

			spi3m0-pins {
				rockchip,pins = <0x04 0x0b 0x04 0x11f 0x04 0x08 0x04 0x11f 0x04 0x0a 0x04 0x11f>;
				phandle = <0xed>;
			};
		};

		pwm2 {

			pwm2m0-pins {
				rockchip,pins = <0x00 0x11 0x01 0x118>;
				phandle = <0x45>;
			};
		};

		spi0-hs {

			spi0m0-pins {
				rockchip,pins = <0x00 0x0d 0x02 0x11f 0x00 0x15 0x02 0x11f 0x00 0x0e 0x02 0x11f>;
				phandle = <0xe1>;
			};
		};

		scr {

			scr-pins {
				rockchip,pins = <0x01 0x02 0x03 0x118 0x01 0x07 0x03 0x11a 0x01 0x03 0x03 0x11a 0x01 0x05 0x03 0x118>;
				phandle = <0xd8>;
			};
		};

		uart1 {

			uart1m0-xfer {
				rockchip,pins = <0x02 0x0b 0x02 0x11a 0x02 0x0c 0x02 0x11a>;
				phandle = <0xee>;
			};
		};

		i2c5 {

			i2c5m0-xfer {
				rockchip,pins = <0x03 0x0b 0x04 0x11d 0x03 0x0c 0x04 0x11d>;
				phandle = <0xdd>;
			};
		};

		sdmmc0 {

			sdmmc0-det {
				rockchip,pins = <0x00 0x04 0x01 0x11a>;
				phandle = <0xc1>;
			};

			sdmmc0-bus4 {
				rockchip,pins = <0x01 0x1d 0x01 0x119 0x01 0x1e 0x01 0x119 0x01 0x1f 0x01 0x119 0x02 0x00 0x01 0x119>;
				phandle = <0xbe>;
			};

			sdmmc0-cmd {
				rockchip,pins = <0x02 0x01 0x01 0x119>;
				phandle = <0xc0>;
			};

			sdmmc0-clk {
				rockchip,pins = <0x02 0x02 0x01 0x119>;
				phandle = <0xbf>;
			};
		};

		pwm0 {

			pwm0m0-pins {
				rockchip,pins = <0x00 0x0f 0x01 0x118>;
				phandle = <0x43>;
			};
		};

		wireless-wlan {

			wifi-host-wake-irq {
				rockchip,pins = <0x03 0x1c 0x00 0x121>;
				phandle = <0x137>;
			};
		};

		i2s3 {

			i2s3m0-lrck {
				rockchip,pins = <0x03 0x04 0x04 0x118>;
				phandle = <0xcc>;
			};

			i2s3m0-sdo {
				rockchip,pins = <0x03 0x05 0x04 0x118>;
				phandle = <0xce>;
			};

			i2s3m0-sdi {
				rockchip,pins = <0x03 0x06 0x04 0x118>;
				phandle = <0xcd>;
			};

			i2s3m0-sclk {
				rockchip,pins = <0x03 0x03 0x04 0x118>;
				phandle = <0xcb>;
			};
		};
	};

	syscon@fdc60000 {
		compatible = "rockchip,rk3568-grf\0syscon\0simple-mfd";
		reg = <0x00 0xfdc60000 0x00 0x10000>;
		phandle = <0x34>;
    };

	scmi-shmem@10f000 {
		compatible = "arm,scmi-shmem";
		reg = <0x00 0x10f000 0x00 0x100>;
		phandle = <0x1b>;
	};

	firmware {

		optee {
			method = "smc";
			compatible = "linaro,optee-tz";
			phandle = <0x13f>;
		};

		sdei {
			method = "smc";
			compatible = "arm,sdei-1.0";
			phandle = <0x141>;
		};

		scmi {
			shmem = <0x1b>;
			#address-cells = <0x01>;
			#size-cells = <0x00>;
			compatible = "arm,scmi-smc";
			phandle = <0x140>;
			arm,smc-id = <0x82000010>;

			protocol@14 {
				#clock-cells = <0x01>;
				reg = <0x14>;
				rockchip,clk-init = <0x41cdb400>;
				phandle = <0x02>;
			};
		};
	};

	mpp-srv {
		rockchip,resetgroup-count = <0x06>;
		rockchip,taskqueue-count = <0x06>;
		compatible = "rockchip,mpp-service";
		status = "okay";
		phandle = <0x6e>;
	};

	dmac@fe530000 {
		clock-names = "apb_pclk";
		interrupts = <0x00 0x0e 0x04 0x00 0x0d 0x04>;
		clocks = <0x20 0x10d>;
		arm,pl330-periph-burst;
		compatible = "arm,pl330\0arm,primecell";
		reg = <0x00 0xfe530000 0x00 0x4000>;
		phandle = <0x41>;
		#dma-cells = <0x01>;
	};

	serial@fe660000 {
		reg-io-width = <0x04>;
		pinctrl-names = "default";
		pinctrl-0 = <0xef>;
		clock-names = "baudclk\0apb_pclk";
		interrupts = <0x00 0x76 0x04>;
		clocks = <0x20 0x123 0x20 0x120>;
		compatible = "rockchip,rk3568-uart\0snps,dw-apb-uart";
		status = "disable";
		reg = <0x00 0xfe660000 0x00 0x100>;
		phandle = <0x1bd>;
		dmas = <0x41 0x04 0x41 0x05>;
		reg-shift = <0x02>;
	};

	fiq-debugger {
		pinctrl-names = "default";
		rockchip,irq-mode-enable = <0x01>;
		rockchip,baudrate = <0x16e360>;
		pinctrl-0 = <0xef>;
		interrupts = <0x00 0xfc 0x08>;
		rockchip,wake-irq = <0x00>;
		compatible = "rockchip,fiq-debugger";
		status = "okay";
		rockchip,serial-id = <0x02>;
	};

	uart4: serial@fe680000 {
		reg-io-width = <0x04>;
		pinctrl-names = "default";
		pinctrl-0 = <0xf1>;
		clock-names = "baudclk\0apb_pclk";
		interrupts = <0x00 0x78 0x04>;
		clocks = <0x20 0x12b 0x20 0x128>;
		compatible = "rockchip,rk3568-uart\0snps,dw-apb-uart";
		status = "disable";
		reg = <0x00 0xfe680000 0x00 0x100>;
		phandle = <0x1bf>;
		dmas = <0x41 0x08 0x41 0x09>;
		reg-shift = <0x02>;
	};

	chosen {
		// bootargs = "storagemedia=emmc rw rootwait earlycon=uart8250,mmio32,0xfe660000 console=ttyFIQ0 root=PARTUUID=root=PARTUUID=614e0000-0000-4b53-8000-1d28000054a9";
		// bootargs = "storagemedia=emmc rw rootwait earlycon=uart8250,mmio32,0xfe660000 console=ttyFIQ0 root=/dev/mmcblk0p5 systemd.mask=NetworkManager.service";
		bootargs = "storagemedia=emmc rw rootwait earlycon=uart8250,mmio32,0xfe660000 console=ttyFIQ0 root=/dev/mmcblk0p5";
		phandle = <0x1eb>;
	};

    hvisor_virtio_device {
        compatible = "hvisor";
        interrupt-parent = <0x01>;
        interrupts = <0x00 0x20 0x01>;
    };
};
